VERSION ""

NS_ :

BS_:
BU_:
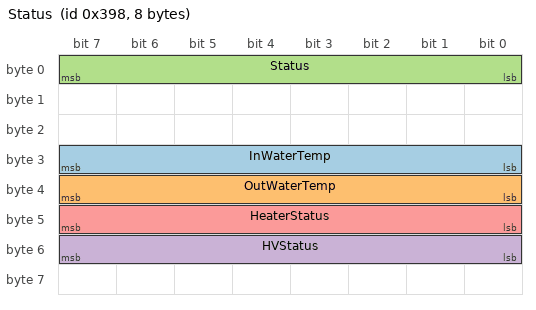
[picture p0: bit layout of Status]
BO_ 920 Status: 8 Vector__XXX
   SG_ InWaterTemp : 24|8@1+ (1,-50) [0|0] "" Vector__XXX
   SG_ OutWaterTemp : 32|8@1+ (1,-50) [0|0] "" Vector__XXX
   SG_ Status : 0|8@1+ (1,0) [0|0] "" Vector__XXX
   SG_ HVStatus : 48|8@1+ (1,0) [0|0] "" Vector__XXX
   SG_ HeaterStatus : 40|8@1+ (1,0) [0|0] "" Vector__XXX

BO_ 392 Control: 8 Vector__XXX

BA_DEF_ BO_ "GenMsgBackgroundColor" STRING ;
BA_DEF_ BO_ "GenMsgForegroundColor" STRING ;
BA_DEF_DEF_ "GenMsgBackgroundColor" "#ffffff";
BA_DEF_DEF_ "GenMsgForegroundColor" "#000000";
VAL_ 920 Status 0 "Not_Ready" 1 "Ready";
VAL_ 920 HVStatus 0 "HV_Present" 9 "No_HV";
VAL_ 920 HeaterStatus 0 "Not_Heating" 64 "Heating";
